# PY32F040xx register map
Vendor: Puya; Series: PY32F0; File version: 1.0.0
CPU: CM0+ r0p1, little endian, no MPU, no FPU, 4 interrupt priority bits
Registers are 32-bit, read-write, reset 0x0 unless marked. A register's access mark holds for its fields unless they carry their own. Offsets are from the block's base; [hi:lo] are bit positions; {n}, {i} and the like mark numbered series; 'fields as' and 'values as' point back to an identical list.

## COMP2 — Comparator2
Base 0x40010210
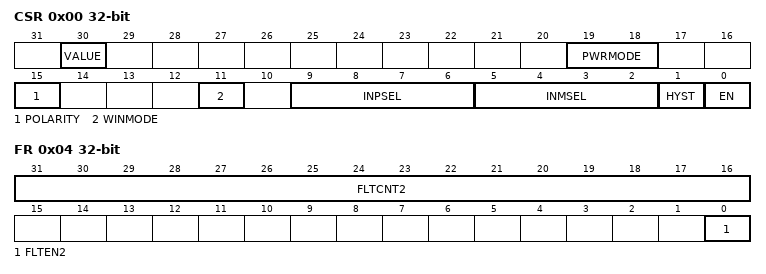
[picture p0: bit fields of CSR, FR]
0x00 CSR — COMP control and status register
  [30] VALUE — Comparator output status
    on read: 0=Low (Comparator output is low); 1=High (Comparator output is high)
  [19:18] PWRMODE — Comparator power mode selector
    0=High speed 250 ua; 1=Medium speed 5 ua
  [15] POLARITY — Comparator polarity selector
    0=NotInverted (Output is not inverted); 1=Inverted (Output is inverted)
  [11] WINMODE — Comparator non-inverting input selector for window mode
    0=Disabled; 1=Enabled
  [9:6] INPSEL — Comparator signal selector for non-inverting input
    {v}=Inp{v} (COMP1_INP{v} from PC{v}) (v=0..3); {v}=Inp{v} (COMP1_INP{v} from PA{v-4}) (v=4..11); 12=Inp12 (COMP1_INP12 from PB4); 13=Inp13 (COMP1_INP13 from PB5); 14=Inp14 (COMP1_INP14 from PB6)
  [5:2] INMSEL — Comparator signal selector for inverting input INM
    {v}=Inm{v} (COMP1_INM{v} from PA{v}) (v=0..7); 8=Inm8 (COMP1_INM8 from PC4); 9=Inm9 (COMP1_INM9 from PC5); 10=Inm11 (COMP1_INM11 from resistor voltage divider); 11=Inm12 (COMP1_INM12 from TS_VIN); 12=Inm13 (COMP1_INM13 from VREF1P2); 13=Inm14 (COMP1_INM14 from VREFBUF); 14=Inm15 (COMP1_INM15 from OPA1_VIN)
  [1] HYST — Comparator hysteresis enable selector
    0=No (no Comp1 hysteresis); 1=Yes (Comp1 hysteresis voltage approx 20mV)
  [0] EN — COMP enable bit
    0=Disabled (Comparator 1 disabled); 1=Enabled (Comparator 1 enabled)
0x04 FR — Comparator Filter register
  [31:16] FLTCNT2 — Comparator filter and counter
  [0] FLTEN2 — Filter enable bit
    0=Disabled (Comparator digital filter disabled); 1=Enabled (Comparator digital filter enabled)

## CRC — CRC calculation unit
Base 0x40023000
0x00 DR reset 0xFFFFFFFF — Data register
  [31:0] DR — Data Register
0x04 IDR — Independent Data register
  [7:0] IDR
0x08 CR wo — Control register
  [0] RESET — Reset bit
    1=Resets the CRC calculation unit and sets the data register to 0xFFFF FFFF

## CTC
Base 0x40006C00
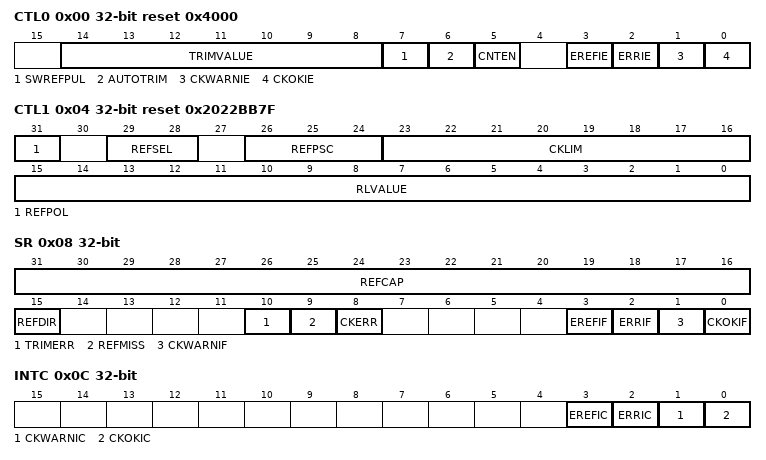
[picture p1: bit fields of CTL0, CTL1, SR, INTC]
0x00 CTL0 reset 0x4000
  [14:8] TRIMVALUE, [7] SWREFPUL wo, [6] AUTOTRIM, [5] CNTEN, [3] EREFIE, [2] ERRIE, [1] CKWARNIE, [0] CKOKIE
0x04 CTL1 reset 0x2022BB7F
  [31] REFPOL, [29:28] REFSEL, [26:24] REFPSC, [23:16] CKLIM, [15:0] RLVALUE
0x08 SR ro
  [31:16] REFCAP, [15] REFDIR, [10] TRIMERR, [9] REFMISS, [8] CKERR, [3] EREFIF, [2] ERRIF, [1] CKWARNIF, [0] CKOKIF
0x0C INTC wo
  [3] EREFIC, [2] ERRIC, [1] CKWARNIC, [0] CKOKIC

## DBG — Debug support
Base 0x40015800
0x00 IDCODE ro — MCU Device ID Code Register
  [30:0] REV_ID
  [31:0] CODE — DBG ID code register
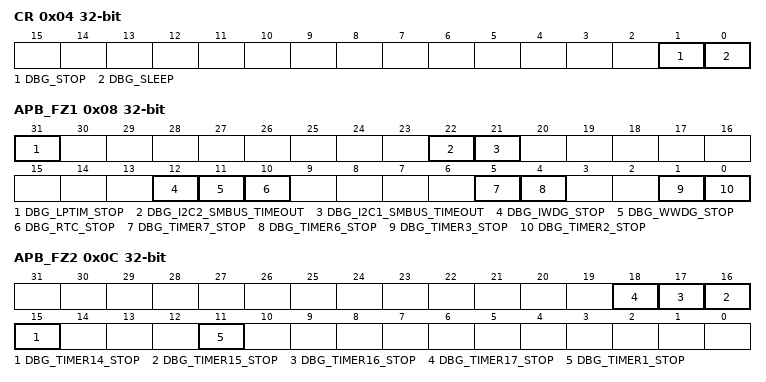
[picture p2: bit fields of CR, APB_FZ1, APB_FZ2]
0x04 CR — Debug MCU Configuration Register
  [1] DBG_STOP — Debug Stop Mode
    0=Disabled (Debug Stop Mode Disabled); 1=Enabled (Debug Stop Mode Enabled)
  [0] DBG_SLEEP — Debug Sleep Mode
0x08 APB_FZ1 — APB Freeze Register1
  [31] DBG_LPTIM_STOP — Debug LPTIM stopped when Core is halted
    0=Continue (LPTIMx counter clock is fed even if the core is halted); 1=Stop (LPTIMx counter clock is stopped when the core is halted)
  [22] DBG_I2C2_SMBUS_TIMEOUT ro
  [21] DBG_I2C1_SMBUS_TIMEOUT
  [12] DBG_IWDG_STOP — Debug Independent Wachdog stopped when Core is halted
    0=Continue (The independent watchdog counter clock continues even if the core is halted); 1=Stop (The independent watchdog counter clock is stopped when the core is halted)
  [11] DBG_WWDG_STOP — Debug Window Wachdog stopped when Core is halted
    0=Continue (The window watchdog counter clock continues even if the core is halted); 1=Stop (The window watchdog counter clock is stopped when the core is halted)
  [10] DBG_RTC_STOP — Debug RTC stopped when Core is halted
    0=Continue (The clock of the RTC counter is fed even if the core is halted); 1=Stop (The clock of the RTC counter is stopped when the core is halted)
  [5] DBG_TIMER7_STOP — Debug Timer 7 stopped when Core is halted
    0=Continue (The counter clock of TIMx is fed even if the core is halted); 1=Stop (The counter clock of TIMx is stopped when the core is halted)
  [4] DBG_TIMER6_STOP — Debug Timer 6 stopped when Core is halted
    values as DBG_TIMER7_STOP
  [1] DBG_TIMER3_STOP — Debug Timer 3 stopped when Core is halted
    values as DBG_TIMER7_STOP
  [0] DBG_TIMER2_STOP — Debug Timer 2 stopped when Core is halted
    values as DBG_TIMER7_STOP
0x0C APB_FZ2 — APB Freeze Register2
  [all] fields
    values as APB_FZ1.DBG_TIMER7_STOP
  [n+1] DBG_TIMER{n}_STOP (n=14..17) — Debug Timer {n} stopped when Core is halted
  [11] DBG_TIMER1_STOP — Debug Timer 1 stopped when Core is halted
